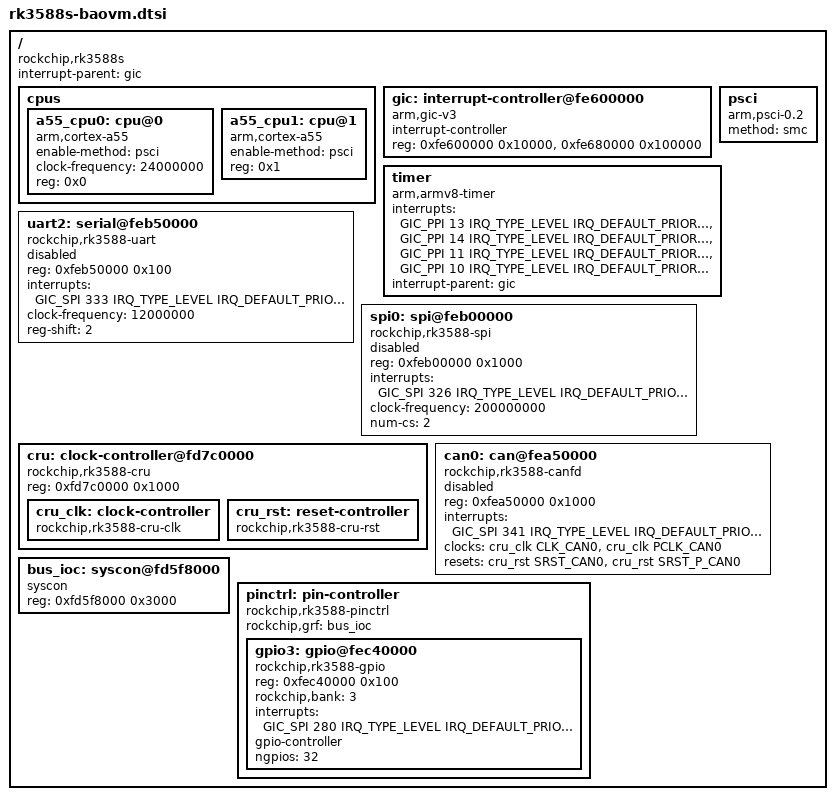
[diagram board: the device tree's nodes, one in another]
/*
 * Copyright (c) 2025 Syswonder
 * SPDX-License-Identifier: Apache-2.0
 */

#include <mem.h>
#include <arm64/armv8-a.dtsi>
#include <zephyr/dt-bindings/interrupt-controller/arm-gic.h>
#include <zephyr/dt-bindings/clock/rk3588-cru.h>
#include <zephyr/dt-bindings/reset/rk3588-cru-reset.h>
#include <zephyr/dt-bindings/pinctrl/rockchip-rk3588-pinctrl.h>

/ {
	#address-cells = <1>;
	#size-cells = <1>;

	compatible = "rockchip,rk3588s";
	interrupt-parent = <&gic>;

	cpus {
		#address-cells = <1>;
		#size-cells = <0>;

		a55_cpu0: cpu@0 {
			device_type = "cpu";
			compatible = "arm,cortex-a55";
			enable-method = "psci";
			clock-frequency = <24000000>;
			reg = <0x0>;
		};

		a55_cpu1: cpu@1 {
			device_type = "cpu";
			compatible = "arm,cortex-a55";
			enable-method = "psci";
			reg = <0x1>;
		};
	};

	gic: interrupt-controller@fe600000 {
		#address-cells = <1>;
		compatible = "arm,gic-v3", "arm,gic";
		#interrupt-cells = <4>;
		interrupt-controller;

		reg = <0xfe600000 0x10000>, /* GICD */
		      <0xfe680000 0x100000>; /* GICR */
		status = "okay";
	};

	psci {
		compatible = "arm,psci-0.2", "arm,psci";
		method = "smc";
	};

	timer {
		compatible = "arm,armv8-timer";
		interrupts = <GIC_PPI 13 IRQ_TYPE_LEVEL IRQ_DEFAULT_PRIORITY>,
			     <GIC_PPI 14 IRQ_TYPE_LEVEL IRQ_DEFAULT_PRIORITY>,
			     <GIC_PPI 11 IRQ_TYPE_LEVEL IRQ_DEFAULT_PRIORITY>,
			     <GIC_PPI 10 IRQ_TYPE_LEVEL IRQ_DEFAULT_PRIORITY>;
		interrupt-parent = <&gic>;
	};

	uart2: serial@feb50000 {
		compatible = "rockchip,rk3588-uart", "ns16550";
		reg = <0xfeb50000 0x100>;
		interrupts = <GIC_SPI 333 IRQ_TYPE_LEVEL IRQ_DEFAULT_PRIORITY>;
		clock-frequency = <12000000>;
		reg-shift = <2>;
		status = "disabled";
	};

	spi0: spi@feb00000 {
		compatible = "rockchip,rk3588-spi";
		reg = <0xfeb00000 0x1000>;
		interrupts = <GIC_SPI 326 IRQ_TYPE_LEVEL IRQ_DEFAULT_PRIORITY>;
		clock-frequency = <200000000>;
		num-cs = <2>;
		#address-cells = <1>;
		#size-cells = <0>;
		status = "disabled";
	};

	cru: clock-controller@fd7c0000 {
		compatible = "rockchip,rk3588-cru";
		/*
		 * Only the first 4 KiB of the CRU is mapped: all clock gate and
		 * reset registers used by this tree live in that window. Keeping
		 * the mapping small also minimises the Bao passthrough.
		 */
		reg = <0xfd7c0000 0x1000>;
		status = "okay";

		cru_clk: clock-controller {
			compatible = "rockchip,rk3588-cru-clk";
			#clock-cells = <1>;
			status = "okay";
		};

		cru_rst: reset-controller {
			compatible = "rockchip,rk3588-cru-rst";
			#reset-cells = <1>;
			status = "okay";
		};
	};

	can0: can@fea50000 {
		compatible = "rockchip,rk3588-canfd";
		reg = <0xfea50000 0x1000>;
		interrupts = <GIC_SPI 341 IRQ_TYPE_LEVEL IRQ_DEFAULT_PRIORITY>;
		clocks = <&cru_clk CLK_CAN0>, <&cru_clk PCLK_CAN0>;
		clock-names = "baud", "pclk";
		resets = <&cru_rst SRST_CAN0>, <&cru_rst SRST_P_CAN0>;
		reset-names = "core", "apb";
		status = "disabled";
	};

	bus_ioc: syscon@fd5f8000 {
		compatible = "syscon";
		reg = <0xfd5f8000 0x3000>;
	};

	pinctrl: pin-controller {
		compatible = "rockchip,rk3588-pinctrl";
		rockchip,grf = <&bus_ioc>;
		#address-cells = <1>;
		#size-cells = <1>;
		ranges;

		gpio3: gpio@fec40000 {
			compatible = "rockchip,rk3588-gpio";
			reg = <0xfec40000 0x100>;
			rockchip,bank = <3>;
			interrupts = <GIC_SPI 280 IRQ_TYPE_LEVEL IRQ_DEFAULT_PRIORITY>;
			gpio-controller;
			#gpio-cells = <2>;
			ngpios = <32>;
		};
	};
};

#include "rk3588-pinctrl.dtsi"
